# KM1M7CF05 register map
Vendor: Nuvoton Technology Corporation Japan; Series: KM1M7CF; File version: 1.0.3
CPU: CM7 r1p2, little endian, MPU, FPU, double-precision FPU, I-cache, D-cache, ITCM, DTCM, 4 interrupt priority bits
Registers are 16-bit, access per field, no defined reset value unless marked. A register's access mark holds for its fields unless they carry their own. Offsets are from the block's base; [hi:lo] are bit positions; {n}, {i} and the like mark numbered series; 'fields as' and 'values as' point back to an identical list.

## WDT — Watchdog Timer
Base 0x40004000
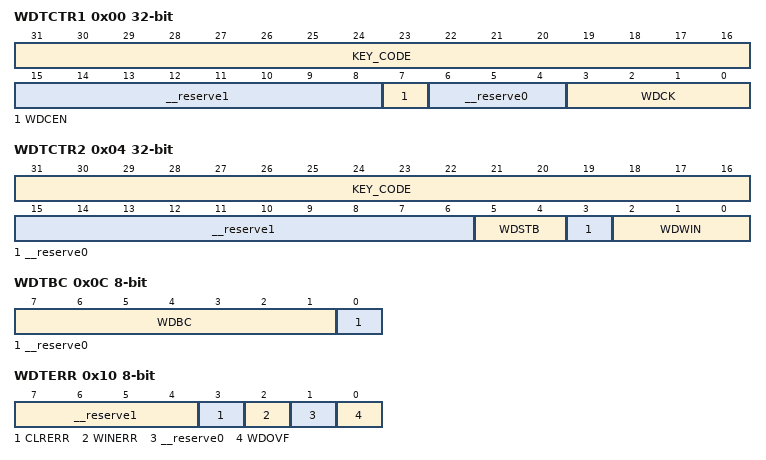
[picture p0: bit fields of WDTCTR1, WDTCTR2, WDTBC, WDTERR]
0x00 WDTCTR1 32-bit — Watchdog Timer Control Register 1
  [31:16] KEY_CODE wo — Register Key
  [15:8] __reserve1 ro — "0" is always read out.
  [7] WDCEN rw — WDT count enable
  [6:4] __reserve0 ro — "0" is always read out.
  [3:0] WDCK rw — Selection of binary counter clock source
0x04 WDTCTR2 32-bit — Watchdog Timer Control Register 2
  [31:16] KEY_CODE wo — Register Key
  [15:6] __reserve1 ro — "0" is always read out.
  [5:4] WDSTB rw — WDT count control in standby mode (SLEEP mode, DEEPSLEEP mode)
  [3] __reserve0 ro — "0" is always read out.
  [2:0] WDWIN rw — Settings of the time WDT counter can be cleared (window open period)
0x08 WDTCLR 8-bit wo — Watchdog Timer Clear Register
  [7:0] WDCL — Writing "0xA5" clears WDT counter.
0x0C WDTBC 8-bit ro — Watchdog Timer Binary Counter
  [7:1] WDBC — Value of WDT binary counter is read out.
  [0] __reserve0 — "0" is always read out.
0x10 WDTERR 8-bit ro — Watchdog Timer Error Flag Register
  [7:4] __reserve1 — "0" is always read out.
  [3] CLRERR — Occurrence of WDT clear data error
  [2] WINERR — Occurrence of WDT window error
  [1] __reserve0 — "0" is always read out.
  [0] WDOVF — Occurrence of WDT overflow error
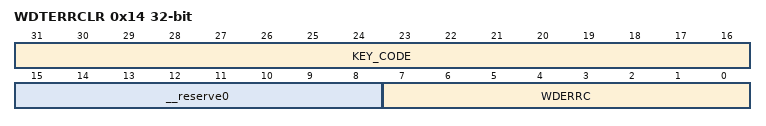
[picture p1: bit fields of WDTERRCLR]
0x14 WDTERRCLR 32-bit — Watchdog Timer Error Flag Clear Register
  [31:16] KEY_CODE wo — Register Key
  [15:8] __reserve0 ro — "0" is always read out.
  [7:0] WDERRC wo — The corresponding bit of WDTERR is cleared by writing "1" to each bit.

## CRC — CRC Calculation Circuit
Base 0x40009000
0x00 CRC0DATA_MSB 32-bit wo — CRC0 Data Register MSB 1st
  [31:0] DATA_MSB — Set the data for CRC calculation in 32-bit units. The calculation is handled as Most Significant Bit (MSB) First.
0x04 CRC0DATA_LSB 32-bit wo — CRC0 Data Register LSB 1st
  [31:0] DATA_LSB — Set the data for CRC calculation in 32-bit units. The calculation is handled as Least Significant Bit (LSB) First.
0x08 CRC0RES_MSB 32-bit rw — CRC0 Checksum Register MSB 1st
  [31:0] RES_MSB — A read access to this register reads out the CRC0 checksum value with MSB First.
0x0C CRC0RES_LSB 32-bit ro — CRC0 Checksum Register LSB 1st
  [31:0] RES_LSB — A read access to this register reads out CRC0 checksum value with LSB First.
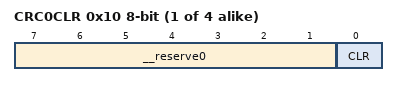
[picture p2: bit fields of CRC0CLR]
{0x10+0x20*i} CRC{i}CLR 8-bit (i=0..3) — CRC{i} Clear Register
  [7:1] __reserve0 ro — "0" is always read out.
  [0] CLR wo — Set CRC{i} seed value.
0x20 CRC1DATA_MSB 8-bit wo — CRC1 Data Register MSB 1st
  [7:0] DATA_MSB — Set the data for CRC calculation in 8-bit units. The calculation is handled as Most Significant Bit (MSB) First.
{0x4+0x20*i} CRC{i}DATA_LSB 8-bit wo (i=1..3) — CRC{i} Data Register LSB 1st
  [7:0] DATA_LSB — Set the data for CRC calculation in 8-bit units. The calculation is handled as Least Significant Bit (LSB) First.
0x28 CRC1RES_MSB rw — CRC1 Checksum Register MSB 1st
  [15:0] RES_MSB — A read access to this register reads out the CRC1 checksum value with MSB First.
0x2C CRC1RES_LSB ro — CRC1 Checksum Register LSB 1st
  [15:0] RES_LSB — A read access to this register reads out CRC1 checksum value with LSB First.
0x40 CRC2DATA_MSB 8-bit wo — CRC2 Data Register MSB 1st
  fields as CRC1DATA_MSB
0x48 CRC2RES_MSB rw — CRC2 Checksum Register MSB 1st
  [15:0] RES_MSB — A read access to this register reads out the CRC2 checksum value with MSB First.
0x4C CRC2RES_LSB ro — CRC2 Checksum Register LSB 1st
  [15:0] RES_LSB — A read access to this register reads out CRC2 checksum value with LSB First.
0x60 CRC3DATA_MSB 8-bit wo — CRC3Data Register MSB 1st
  fields as CRC1DATA_MSB
0x68 CRC3RES_MSB 8-bit rw — CRC3 Checksum Register MSB 1st
  [7:0] RES_MSB — A read access to this register reads out the CRC3 checksum value with MSB First.
0x6C CRC3RES_LSB 8-bit ro — CRC3 Checksum Register LSB 1st
  [7:0] RES_LSB — A read access to this register reads out CRC3 checksum value with LSB First.

## LIN
Base 0x40050274
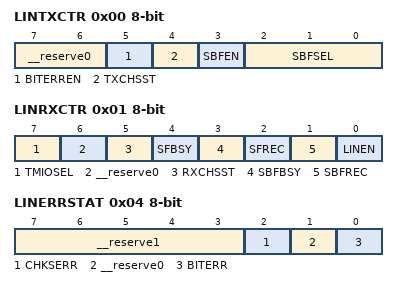
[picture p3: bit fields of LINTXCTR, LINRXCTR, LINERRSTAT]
0x00 LINTXCTR 8-bit — LIN Transmission Control Register
  [7:6] __reserve0 ro — "0" is always read out.
  [5] BITERREN rw — Bit error detection function selection
  [4] TXCHSST rw — Checksum operation for transmission
  [3] SBFEN rw — Synch Break field transmission trigger/monitor (*1)
  [2:0] SBFSEL rw — Synch Break field transmission width selection
0x01 LINRXCTR 8-bit — LIN Reception Control Register
  [7] TMIOSEL rw — Selection of clock source for Timer 12
  [6] __reserve0 rw — This bit must be set to "0".
  [5] RXCHSST rw — Checksum operation for reception
  [4] SFBSY ro — Synch field reception busy
  [3] SBFBSY ro — Synch Break field reception busy
  [2] SFREC rw — Enable Synch field reception
  [1] SBFREC rw — Enable Wake up signal and Synch Break field reception
  [0] LINEN rw — Enable LIN communication
0x04 LINERRSTAT 8-bit ro — LIN Error Status Register
  [7:3] __reserve1 — "0" is always read out.
  [2] CHKSERR — Checksum error detection (*1) (*2)
  [1] __reserve0 — "0" is always read out.
  [0] BITERR — Bit error detection (*3)
0x08 LINTXCHKS 8-bit ro — LIN Transmission Checksum Register
  [7:0] TXCHKS — Checksum value for the transmission data is read out.
0x09 LINRXCHKS 8-bit ro — LIN Reception Checksum Register
  [7:0] RXCHKS — Checksum value for the reception data is read out.

## CMP — Comparator
Base 0x40054000
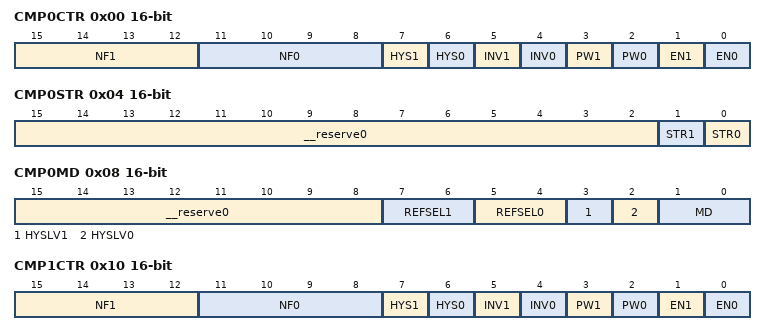
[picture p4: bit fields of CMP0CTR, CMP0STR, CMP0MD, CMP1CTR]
0x00 CMP0CTR rw — Comparator 0 Control Register
  [15:12] NF1 — Selection of comparator n1 output noise filter
  [11:8] NF0 — Selection of comparator n0 output noise filter
  [7] HYS1 — CMPn1 hysteresis setting
  [6] HYS0 — CMPn0 hysteresis setting
  [5] INV1 — Selection of CMPn1 comparator detection polarity
  [4] INV0 — Selection of CMPn0 comparator detection polarity
  [3] PW1 — Operation of the CMPn1 comparator
  [2] PW0 — Operation of the CMPn0 comparator
  [1] EN1 — Start of the comparator n1 comparison
  [0] EN0 — Start of the comparator n0 comparison
0x04 CMP0STR ro — Comparator 0 Status Register
  [15:2] __reserve0 — "0" is always read out.
  [1] STR1 — Detection state of CMPn1
  [0] STR0 — Detection state of CMPn0
0x08 CMP0MD — Comparator 0 Mode Register
  [15:8] __reserve0 ro — "0" is always read out.
  [7:6] REFSEL1 rw — CMPn1reference voltage
  [5:4] REFSEL0 rw — CMPn0 refernce voltage
  [3] HYSLV1 rw — CMPn1 hysteresis width (*)
  [2] HYSLV0 rw — CMPn0 hysteresis width (*)
  [1:0] MD rw — CMPn operating mode
0x10 CMP1CTR rw — Comparator 1 Control Register
  fields as CMP0CTR
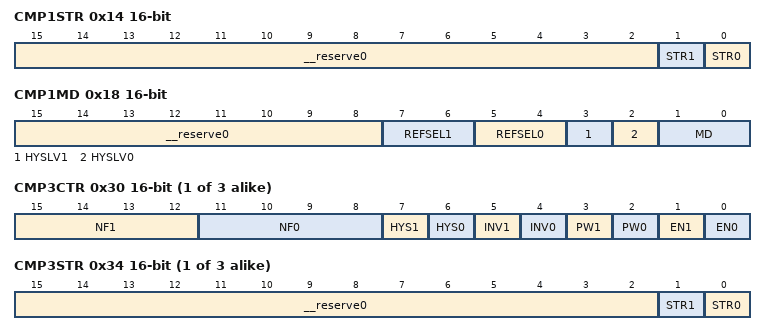
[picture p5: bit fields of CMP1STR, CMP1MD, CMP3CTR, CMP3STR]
0x14 CMP1STR ro — Comparator 1 Status Register
  fields as CMP0STR
0x18 CMP1MD — Comparator 1 Mode Register
  fields as CMP0MD
{0x0+0x10*i} CMP{i}CTR rw (i=3..5) — Comparator {i} Control Register
  fields as CMP0CTR
{0x4+0x10*i} CMP{i}STR ro (i=3..5) — Comparator {i} Status Register
  fields as CMP0STR
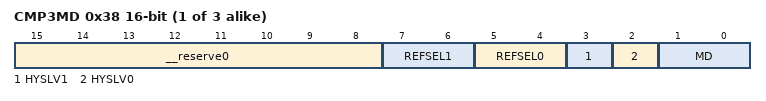
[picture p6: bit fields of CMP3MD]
{0x8+0x10*i} CMP{i}MD (i=3..5) — Comparator {i} Mode Register
  fields as CMP0MD

## PWRDET — Power Supply Voltage Detection
Base 0x40056000
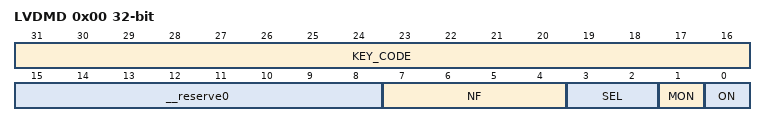
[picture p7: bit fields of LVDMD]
0x00 LVDMD 32-bit — Power Supply Voltage Detection Control Register
  [31:16] KEY_CODE wo — Register Key
  [15:8] __reserve0 ro — "0" is always read out.
  [7:4] NF rw — Selection of power supply voltage detection signal noise filter
  [3:2] SEL rw — Power supply voltage detection level selection (*)
  [1] MON ro — Power supply voltage monitor bit
  [0] ON rw — Power supply voltage detection function control
